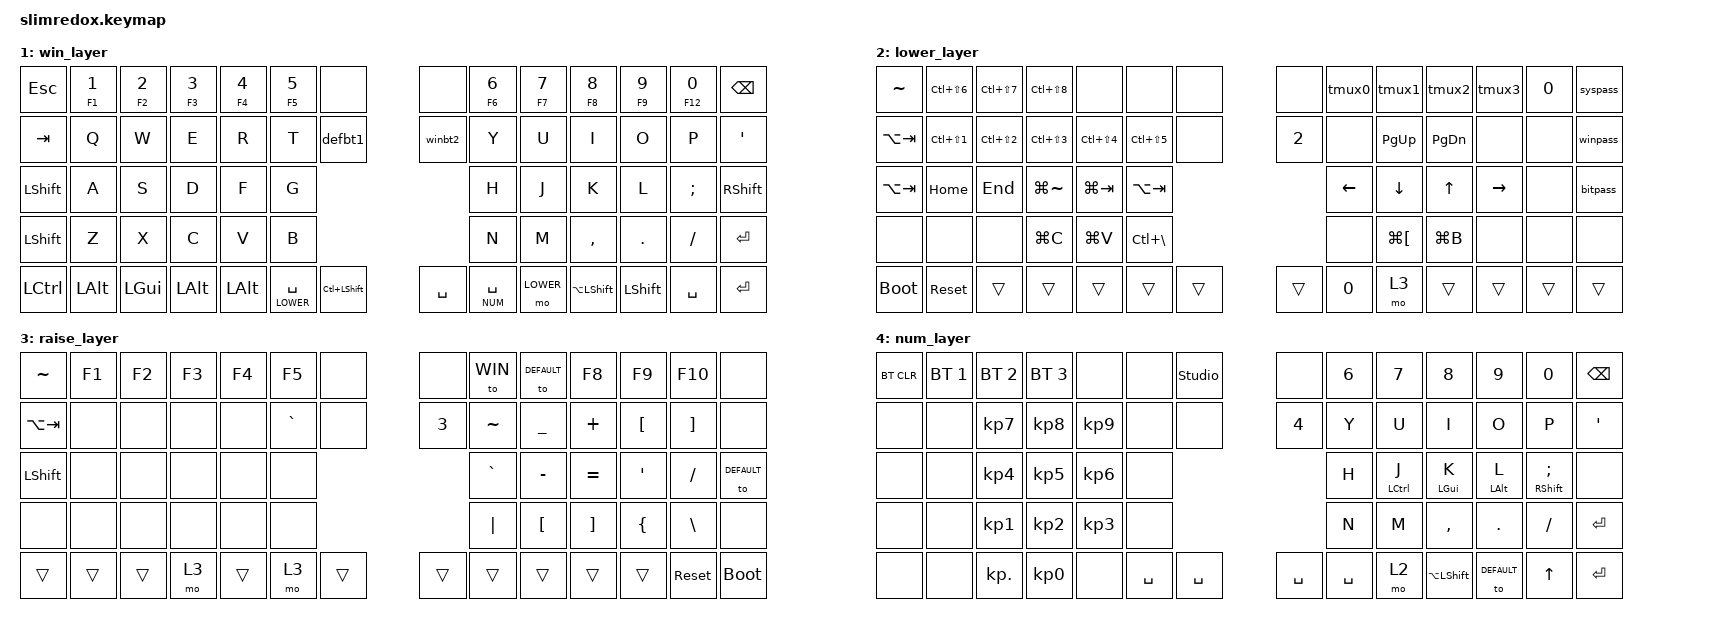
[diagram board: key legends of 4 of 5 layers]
/*
 * Copyright (c) 2021 The ZMK Contributors
 *
 * SPDX-License-Identifier: MIT
 */

#include <behaviors.dtsi>
#include <dt-bindings/zmk/keys.h>
#include <dt-bindings/zmk/bt.h>
#include <dt-bindings/zmk/ext_power.h>
#include <dt-bindings/zmk/outputs.h>
#include <syspass.h>

#define xxx &none
#define ___ &trans
#define ph1 &kp LC(LS(N1))
#define ph2 &kp LC(LS(N2))
#define ph3 &kp LC(LS(N3))
#define ph4 &kp LC(LS(N4))
#define ph5 &kp LC(LS(N5))
#define ph6 &kp LC(LS(N6))
#define ph7 &kp LC(LS(N7))
#define ph8 &kp LC(LS(N8))
#define ph9 &kp LC(LS(N9))
#define nvtc &kp LC(BSLH)
#define mv &macro_wait_time 70

#define DEFAULT 0
#define WIN 1
#define LOWER 2
#define RAISE 3
#define NUM 4


/ {
    macros {
        tmux0: tmux0{
            compatible = "zmk,behavior-macro";
            #binding-cells = <0>;
            bindings = <&kp LC(B)>, <&kp N0>;
        };
        tmux1: tmux1{
            compatible = "zmk,behavior-macro";
            #binding-cells = <0>;
            bindings = <&kp LC(B)>, <&kp N1>;
        };
        tmux2: tmux2{
            compatible = "zmk,behavior-macro";
            #binding-cells = <0>;
            bindings = <&kp LC(B)>, <&kp N2>;
        };
        tmux3: tmux3{
            compatible = "zmk,behavior-macro";
            #binding-cells = <0>;
            bindings = <&kp LC(B)>, <&kp N3>;
        };
        defbt1: defbt1{
            compatible = "zmk,behavior-macro";
            #binding-cells = <0>;
            bindings = <&to DEFAULT>, <&bt BT_SEL 1>;
        };
        winbt2: winbt2{
            compatible = "zmk,behavior-macro";
            #binding-cells = <0>;
            bindings = <&to WIN>, <&bt BT_SEL 2>;
        };
        winpass: winpass{
            compatible = "zmk,behavior-macro";
            #binding-cells = <0>;
            bindings = WINPASS;
        };
        syspass: syspass{
            compatible = "zmk,behavior-macro";
            #binding-cells = <0>;
            bindings = SYSPASS;
        };
        bitpass: bitpass{
            compatible = "zmk,behavior-macro";
            #binding-cells = <0>;
            bindings = <&macro_wait_time 50>, BITPASS;
        };
    };
};



/ {
  behaviors {
        bhm: balanced_homerow_mods {
            compatible = "zmk,behavior-hold-tap";
            #binding-cells = <2>;
            tapping-term-ms = <300>;    // <---[[moderate duration]]
            quick-tap-ms = <0>;
            flavor = "balanced";
            bindings = <&kp>, <&kp>;
        };
        lhm: balanced_homerow_mods2 {
            compatible = "zmk,behavior-hold-tap";
            #binding-cells = <2>;
            tapping-term-ms = <300>;    // <---[[moderate duration]]
            quick-tap-ms = <0>;
            flavor = "hold-preferred";
            bindings = <&mo>, <&kp>;
        };
        btp: bluetooth_clear_protection {
            compatible = "zmk,behavior-hold-tap";
            #binding-cells = <2>;
            tapping-term-ms = <1000>;    // <---[[moderate duration]]
            quick-tap-ms = <0>;
            flavor = "hold-preferred";
            bindings = <&kp>, <&kp>;
        };
        hw_soft_off: hw_soft_off {
            compatible = "zmk,behavior-soft-off";
            #binding-cells = <0>;
            hold-time-ms = <3000>;
        };
  };

  keymap {
        compatible =  "zmk,keymap" ;

        default_layer {
            bindings = <
// ┌──────────┬──────────┬──────────┬──────────┬──────────┬──────────┐                                                  ┌───────────┬───────────┬──────────┬──────────┬──────────┬──────────┐
       &kp LC(F12) &kp N1    &kp N2     &kp N3     &kp N4     &kp N5    &hw_soft_off                            &hw_soft_off       &kp N6     &kp N7       &kp N8    &kp N9      &kp N0    &kp KP_DOT
// ├──────────┼──────────┼──────────┼──────────┼──────────┼──────────┼──────────┐                           ┌───────────┼───────────┼───────────┼──────────┼──────────┼──────────┼──────────┤
        nvtc     &kp Q     &kp W      &kp E      &kp R      &kp T      &to DEFAULT                         &to WIN       &kp Y      &kp U        &kp I     &kp O       &kp P     &kp LC(W)
// ├──────────┼──────────┼──────────┼──────────┼──────────┼──────────┼──────────┤                           ├───────────┼───────────┼───────────┼──────────┼──────────┼──────────┼──────────┤
       &kp LC(F10) &bhm LSHIFT A &bhm LALT S  &bhm LGUI D &bhm LCTRL F &kp G                                             &kp H   &bhm LCTRL J &bhm LGUI K  &bhm LALT L  &bhm RSHIFT SEMI &kp LC(N)
// ├──────────┼──────────┼──────────┼──────────┼──────────┼──────────┼──────────┼──────────┐     ┌──────────┼───────────┼───────────┼───────────┼──────────┼──────────┼──────────┼──────────┤
       &kp LC(F11) &kp Z     &kp X      &kp C      &kp V      &kp B                                                           &kp N      &kp M       &kp COMMA  &kp DOT    &kp FSLH  xxx
// ├──────────┼──────────┼──────────┼──────────┼──────────┼──────────┼──────────┼──────────┤     ├──────────┼───────────┼───────────┼───────────┼──────────┼──────────┼──────────┼──────────┤
      &kp LC(F9) &kp LALT  &kp LCMD   &kp TAB        &lhm LOWER ESC  &lhm LOWER SPACE  &lhm NUM LC(SPACE)             &kp LG(SPACE)    &lhm NUM SPACE  &lhm RAISE RET  &kp BSPC   &kp DOWN   &kp TILDE &kp LG(LS(R)) xxx
// └──────────┴──────────┴──────────┴──────────┘          └──────────┴──────────┴──────────┘     └──────────┴───────────┴───────────┘           └──────────┴──────────┴──────────┴──────────┘
            >;

        };

        win_layer {
            bindings = <
// ┌──────────┬──────────┬──────────┬──────────┬──────────┬──────────┐                                                  ┌───────────┬───────────┬──────────┬──────────┬──────────┬──────────┐
     &kp ESC     &bhm F1 N1    &bhm F2 N2     &bhm F3 N3     &bhm F4 N4     &bhm F5 N5 xxx                     xxx  &bhm F6 N6     &bhm F7 N7  &bhm F8 N8    &bhm F9 N9   &bhm F12 N0    &kp BSPC
// ├──────────┼──────────┼──────────┼──────────┼──────────┼──────────┼──────────┐                           ┌───────────┼───────────┼───────────┼──────────┼──────────┼──────────┼──────────┤
     &kp TAB     &kp Q     &kp W      &kp E      &kp R      &kp T      &defbt1                                  &winbt2     &kp Y      &kp U        &kp I     &kp O       &kp P     &kp SQT
// ├──────────┼──────────┼──────────┼──────────┼──────────┼──────────┼──────────┤                           ├───────────┼───────────┼───────────┼──────────┼──────────┼──────────┼──────────┤
     &kp LSHFT   &kp A     &kp S      &kp D      &kp F      &kp G                                                          &kp H      &kp J        &kp K     &kp L      &kp SEMI   &kp RSHFT
// ├──────────┼──────────┼──────────┼──────────┼──────────┼──────────┼──────────┼──────────┐     ┌──────────┼───────────┼───────────┼───────────┼──────────┼──────────┼──────────┼──────────┤
     &kp LSHFT   &kp Z     &kp X      &kp C      &kp V      &kp B                                                          &kp N      &kp M       &kp COMMA  &kp DOT    &kp FSLH   &kp RET
// ├──────────┼──────────┼──────────┼──────────┼──────────┼──────────┼──────────┼──────────┤     ├──────────┼───────────┼───────────┼───────────┼──────────┼──────────┼──────────┼──────────┤
     &kp LCTRL   &kp LALT  &kp LGUI   &kp LALT     &kp LALT  &lhm LOWER SPACE  &kp LC(LSHIFT)     &kp SPACE  &lhm NUM SPACE     &mo LOWER                &kp LA(LSHFT) &kp LSHIFT  &kp SPACE   &kp RET
// └──────────┴──────────┴──────────┴──────────┘          └──────────┴──────────┴──────────┘     └──────────┴───────────┴───────────┘           └──────────┴──────────┴──────────┴──────────┘
            >;
    };

        lower_layer {
            bindings = <

// ┌──────────┬──────────┬──────────┬──────────┬──────────┬──────────┐                                                  ┌───────────┬───────────┬──────────┬──────────┬──────────┬──────────┐
    &kp TILDE   ph6         ph7        ph8        xxx        xxx        xxx                                     xxx         &tmux0     &tmux1      &tmux2    &tmux3      &kp N0    &syspass
// ├──────────┼──────────┼──────────┼──────────┼──────────┼──────────┼──────────┐                           ┌───────────┼───────────┼───────────┼──────────┼──────────┼──────────┼──────────┤
   &kp LA(TAB)   ph1        ph2        ph3        ph4       ph5         xxx                                     &kp N2      xxx       &kp PAGE_UP   &kp PAGE_DOWN   xxx  xxx        &winpass
// ├──────────┼──────────┼──────────┼──────────┼──────────┼──────────┼──────────┤                           ├───────────┼───────────┼───────────┼──────────┼──────────┼──────────┼──────────┤
   &kp LA(TAB)  &kp HOME   &kp END    &kp LG(TILDE)  &kp LG(TAB)  &kp LA(TAB)                                             &kp LEFT    &kp DOWN    &kp UP     &kp RIGHT   xxx        &bitpass
// ├──────────┼──────────┼──────────┼──────────┼──────────┼──────────┼──────────┼──────────┐     ┌──────────┼───────────┼───────────┼───────────┼──────────┼──────────┼──────────┼──────────┤
     xxx        xxx        xxx      &kp LG(C) &kp LG(V)   nvtc                                                            xxx      &kp LG(LBKT)  &kp LG(B)  xxx        xxx          xxx
// ├──────────┼──────────┼──────────┼──────────┼──────────┼──────────┼──────────┼──────────┤     ├──────────┼───────────┼───────────┼───────────┼──────────┼──────────┼──────────┼──────────┤
     &bootloader     &sys_reset     &trans     &trans                &trans      &trans     &trans          &trans      &kp N0       &mo 3                  &trans    &trans     &trans      &trans
// └──────────┴──────────┴──────────┴──────────┘          └──────────┴──────────┴──────────┘     └──────────┴───────────┴───────────┘           └──────────┴──────────┴──────────┴──────────┘
            >;
        };

        raise_layer {
            bindings = <
// ┌──────────┬──────────┬──────────┬──────────┬──────────┬──────────┐                                                  ┌───────────┬───────────┬──────────┬──────────┬──────────┬──────────┐
    &kp TILDE    &kp F1     &kp F2     &kp F3     &kp F4     &kp F5       xxx                                     xxx      &to WIN     &to DEFAULT   &kp F8    &kp F9     &kp F10   xxx
// ├──────────┼──────────┼──────────┼──────────┼──────────┼──────────┼──────────┐                           ┌───────────┼───────────┼───────────┼──────────┼──────────┼──────────┼──────────┤
   &kp LA(TAB)   xxx        xxx        xxx        xxx        &kp GRAVE         xxx                                   &kp N3       &kp TILDE    &kp UNDER   &kp PLUS    &kp LBKT   &kp RBKT  xxx   
// ├──────────┼──────────┼──────────┼──────────┼──────────┼──────────┼──────────┤                           ├───────────┼───────────┼───────────┼──────────┼──────────┼──────────┼──────────┤
     &kp LSHFT     xxx        xxx        xxx        xxx        xxx                                                        &kp GRAVE    &kp MINUS   &kp EQUAL   &kp SQT   &kp SLASH  &to DEFAULT
// ├──────────┼──────────┼──────────┼──────────┼──────────┼──────────┼──────────┼──────────┐     ┌──────────┼───────────┼───────────┼───────────┼──────────┼──────────┼──────────┼──────────┤
      xxx        xxx        xxx        xxx        xxx        xxx                                                           &kp PIPE   &kp LBKT    &kp RBKT    &kp LBRC   &kp BSLH   xxx
// ├──────────┼──────────┼──────────┼──────────┼──────────┼──────────┼──────────┼──────────┤     ├──────────┼───────────┼───────────┼───────────┼──────────┼──────────┼──────────┼──────────┤
      &trans     &trans    &trans       &mo 3                &trans      &mo 3     &trans           &trans      &trans     &trans                 &trans      &trans     &sys_reset     &bootloader
// └──────────┴──────────┴──────────┴──────────┘          └──────────┴──────────┴──────────┘     └──────────┴───────────┴───────────┘           └──────────┴──────────┴──────────┴──────────┘
            >;
        };

        num_layer {
            bindings = <
// ┌──────────┬──────────┬──────────┬──────────┬──────────┬──────────┐                                                  ┌───────────┬───────────┬──────────┬──────────┬──────────┬──────────┐
 &bt BT_CLR  &bt BT_SEL 1 &bt BT_SEL 2 &bt BT_SEL 3 xxx       xxx       &studio_unlock                                    xxx          &kp N6     &kp N7       &kp N8    &kp N9      &kp N0    &kp BSPC
// ├──────────┼──────────┼──────────┼──────────┼──────────┼──────────┼──────────┐                           ┌───────────┼───────────┼───────────┼──────────┼──────────┼──────────┼──────────┤
     xxx         xxx       &kp KP_N7 &kp KP_N8  &kp KP_N9     xxx       xxx                                    &kp N4       &kp Y      &kp U        &kp I     &kp O       &kp P     &kp SQT
// ├──────────┼──────────┼──────────┼──────────┼──────────┼──────────┼──────────┤                           ├───────────┼───────────┼───────────┼──────────┼──────────┼──────────┼──────────┤
     xxx         xxx       &kp KP_N4 &kp KP_N5  &kp KP_N6     xxx                                                           &kp H   &bhm LCTRL J &bhm LGUI K  &bhm LALT L  &bhm RSHIFT SEMI  xxx
// ├──────────┼──────────┼──────────┼──────────┼──────────┼──────────┼──────────┼──────────┐     ┌──────────┼───────────┼───────────┼───────────┼──────────┼──────────┼──────────┼──────────┤
     xxx         xxx       &kp KP_N1 &kp KP_N2  &kp KP_N3     xxx                                                         &kp N      &kp M       &kp COMMA  &kp DOT    &kp FSLH   &kp RET
// ├──────────┼──────────┼──────────┼──────────┼──────────┼──────────┼──────────┼──────────┤     ├──────────┼───────────┼───────────┼───────────┼──────────┼──────────┼──────────┼──────────┤
     xxx        xxx        &kp KP_DOT  &kp KP_N0              xxx     &kp SPACE  &kp SPACE        &kp SPACE  &kp SPACE     &mo 2                &kp LA(LSHFT) &to DEFAULT  &kp UP   &kp RET
// └──────────┴──────────┴──────────┴──────────┘          └──────────┴──────────┴──────────┘     └──────────┴───────────┴───────────┘           └──────────┴──────────┴──────────┴──────────┘
            >;
    };

  };  // keymap
};  // root

